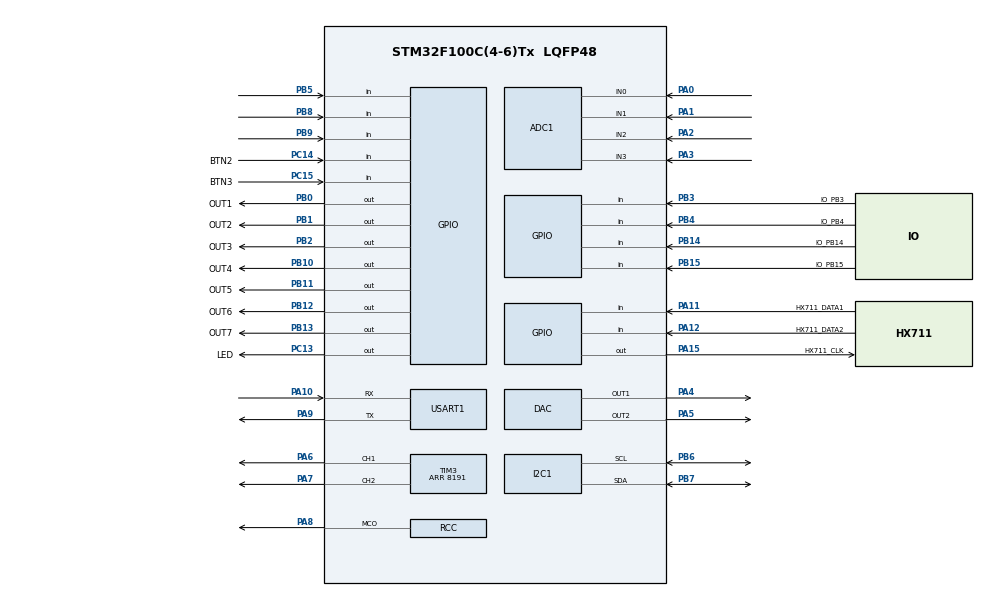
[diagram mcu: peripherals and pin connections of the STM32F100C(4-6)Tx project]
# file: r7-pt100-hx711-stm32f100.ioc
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ADC1.Channel-0\#ChannelRegularConversion=ADC_CHANNEL_0
ADC1.NbrOfConversionFlag=1
ADC1.Rank-0\#ChannelRegularConversion=1
ADC1.SamplingTime-0\#ChannelRegularConversion=ADC_SAMPLETIME_1CYCLE_5
ADC1.master=1
IWDG.Prescaler=IWDG_PRESCALER_32
IWDG.Reload=2000
Mcu.Family=STM32F1
Mcu.Name=STM32F100C(4-6)Tx
Mcu.Package=LQFP48
NVIC.PriorityGroup=NVIC_PRIORITYGROUP_4
PA0-WKUP.Signal=ADCx_IN0
PA1.Signal=ADCx_IN1
PA10.Mode=Asynchronous
PA10.Signal=USART1_RX
PA11.GPIO_Label=HX711_DATA1
PA11.Signal=GPIO_Input
PA12.GPIO_Label=HX711_DATA2
PA12.Signal=GPIO_Input
PA13.Mode=Serial_Wire
PA13.Signal=SYS_JTMS-SWDIO
PA14.Mode=Serial_Wire
PA14.Signal=SYS_JTCK-SWCLK
PA15.GPIO_Label=HX711_CLK
PA15.Signal=GPIO_Output
PA2.Signal=ADCx_IN2
PA3.Signal=ADCx_IN3
PA4.Signal=COMP_DAC1_group
PA5.Signal=COMP_DAC2_group
PA6.Signal=S_TIM3_CH1
PA7.Signal=S_TIM3_CH2
PA8.Mode=Clock-out
PA8.Signal=RCC_MCO
PA9.Mode=Asynchronous
PA9.Signal=USART1_TX
PB0.GPIO_Label=OUT1
PB0.Signal=GPIO_Output
PB1.GPIO_Label=OUT2
PB1.Signal=GPIO_Output
PB10.GPIO_Label=OUT4
PB10.Signal=GPIO_Output
PB11.GPIO_Label=OUT5
PB11.Signal=GPIO_Output
PB12.GPIO_Label=OUT6
PB12.Signal=GPIO_Output
PB13.GPIO_Label=OUT7
PB13.Signal=GPIO_Output
PB14.GPIO_Label=IO_PB14
PB14.Signal=GPIO_Input
PB15.GPIO_Label=IO_PB15
PB15.Signal=GPIO_Input
PB2.GPIO_Label=OUT3
PB2.Signal=GPIO_Output
PB3.GPIO_Label=IO_PB3
PB3.Signal=GPIO_Input
PB4.GPIO_Label=IO_PB4
PB4.Signal=GPIO_Input
PB5.GPIO_PuPd=GPIO_PULLUP
PB5.Signal=GPIO_Input
PB6.Mode=I2C
PB6.Signal=I2C1_SCL
PB7.Mode=I2C
PB7.Signal=I2C1_SDA
PB8.GPIO_PuPd=GPIO_PULLUP
PB8.Signal=GPIO_Input
PB9.GPIO_PuPd=GPIO_PULLUP
PB9.Signal=GPIO_Input
PC13-TAMPER-RTC.GPIO_Label=LED
PC13-TAMPER-RTC.Signal=GPIO_Output
PC14-OSC32_IN.GPIO_Label=BTN2
PC14-OSC32_IN.Signal=GPIO_Input
PC15-OSC32_OUT.GPIO_Label=BTN3
PC15-OSC32_OUT.Signal=GPIO_Input
PD0-OSC_IN.Mode=HSE-External-Oscillator
PD0-OSC_IN.Signal=RCC_OSC_IN
PD1-OSC_OUT.Mode=HSE-External-Oscillator
PD1-OSC_OUT.Signal=RCC_OSC_OUT
ProjectManager.HeapSize=0x200
ProjectManager.StackSize=0x400
ProjectManager.TargetToolchain=STM32CubeIDE
RCC.AHBFreq_Value=24000000
RCC.APB1Freq_Value=24000000
RCC.APB1TimFreq_Value=24000000
RCC.APB2Freq_Value=24000000
RCC.APB2TimFreq_Value=24000000
RCC.HCLKFreq_Value=24000000
RCC.PLLMUL=RCC_PLL_MUL3
RCC.PLLSource=RCC_PLLSOURCE_HSE
RCC.RCC_MCOSource=RCC_MCO1SOURCE_PLLCLK
RCC.SYSCLKFreq_VALUE=24000000
RCC.SYSCLKSource=RCC_SYSCLKSOURCE_PLLCLK
SH.ADCx_IN0.0=ADC1_IN0,IN0
SH.ADCx_IN1.0=ADC1_IN1,IN1
SH.ADCx_IN2.0=ADC1_IN2,IN2
SH.ADCx_IN3.0=ADC1_IN3,IN3
SH.COMP_DAC1_group.0=DAC_OUT1,DAC_OUT1
SH.COMP_DAC2_group.0=DAC_OUT2,DAC_OUT2
SH.S_TIM3_CH1.0=TIM3_CH1,PWM Generation1 CH1
SH.S_TIM3_CH2.0=TIM3_CH2,PWM Generation2 CH2
TIM3.Channel-PWM\ Generation1\ CH1=TIM_CHANNEL_1
TIM3.Channel-PWM\ Generation2\ CH2=TIM_CHANNEL_2
TIM3.Period=8191
USART1.VirtualMode=VM_ASYNC
VP_IWDG_VS_IWDG.Mode=IWDG_Activate
VP_TIM3_VS_ClockSourceINT.Mode=Internal
board=custom

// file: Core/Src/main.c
/* USER CODE BEGIN Header */
/**
  ******************************************************************************
  * @file           : main.c
  * @brief          : Main program body
  ******************************************************************************
  * @attention
  *
  * <h2><center>&copy; Copyright (c) 2020 STMicroelectronics.
  * All rights reserved.</center></h2>
  *
  * This software component is licensed by ST under BSD 3-Clause license,
  * the "License"; You may not use this file except in compliance with the
  * License. You may obtain a copy of the License at:
  *                        opensource.org/licenses/BSD-3-Clause
  *
  ******************************************************************************
  */
/* USER CODE END Header */
#include "main.h"

/* USER CODE BEGIN Includes */

#include <stdio.h>
#include "adc_hx711.h"

/* USER CODE END Includes */

void SystemClock_Config(void);
static void MX_GPIO_Init(void);
static void MX_ADC1_Init(void);
static void MX_DAC_Init(void);
static void MX_I2C1_Init(void);
static void MX_TIM3_Init(void);
static void MX_USART1_UART_Init(void);
static void MX_IWDG_Init(void);

/* USER CODE BEGIN 0 */

int __io_putchar(int ch)
{
	while (!LL_USART_IsActiveFlag_TXE(USART1))
	{};
	LL_USART_TransmitData8(USART1, ch);
	return 0;
}

/* USER CODE END 0 */

int main(void)
{

  /* MCU Configuration--------------------------------------------------------*/

  /* Reset of all peripherals, Initializes the Flash interface and the Systick. */

  LL_APB2_GRP1_EnableClock(LL_APB2_GRP1_PERIPH_AFIO);
  LL_APB1_GRP1_EnableClock(LL_APB1_GRP1_PERIPH_PWR);

  NVIC_SetPriorityGrouping(NVIC_PRIORITYGROUP_4);

  /* System interrupt init*/

  /** NOJTAG: JTAG-DP Disabled and SW-DP Enabled
  */
  LL_GPIO_AF_Remap_SWJ_NOJTAG();

  /* Configure the system clock */
  SystemClock_Config();

  /* Initialize all configured peripherals */
  MX_GPIO_Init();
  MX_ADC1_Init();
  MX_DAC_Init();
  MX_I2C1_Init();
  MX_TIM3_Init();
  MX_USART1_UART_Init();
  MX_IWDG_Init();
  /* USER CODE BEGIN 2 */

  // инициализация ADC
  ADC_HX711_Init();
  /* USER CODE END 2 */

  /* Infinite loop */
  /* USER CODE BEGIN WHILE */
  printf("\r\n---------------------------------\r\n");
  printf("Digital converter PT100\r\n");

  while (1)
  {
	  LL_GPIO_TogglePin(LED_GPIO_Port, LED_Pin);
	  ADC_HX711_Process();

	  LL_IWDG_ReloadCounter(IWDG);

    /* USER CODE END WHILE */

  }
}

void SystemClock_Config(void)
{
  LL_RCC_HSE_Enable();

   /* Wait till HSE is ready */
  while(LL_RCC_HSE_IsReady() != 1)
  {

  }
  LL_RCC_LSI_Enable();

   /* Wait till LSI is ready */
  while(LL_RCC_LSI_IsReady() != 1)
  {

  }
  LL_RCC_PLL_ConfigDomain_SYS(LL_RCC_PLLSOURCE_HSE_DIV_1, LL_RCC_PLL_MUL_3);
  LL_RCC_PLL_Enable();

   /* Wait till PLL is ready */
  while(LL_RCC_PLL_IsReady() != 1)
  {

  }
  LL_RCC_SetAHBPrescaler(LL_RCC_SYSCLK_DIV_1);
  LL_RCC_SetAPB1Prescaler(LL_RCC_APB1_DIV_1);
  LL_RCC_SetAPB2Prescaler(LL_RCC_APB2_DIV_1);
  LL_RCC_SetSysClkSource(LL_RCC_SYS_CLKSOURCE_PLL);

   /* Wait till System clock is ready */
  while(LL_RCC_GetSysClkSource() != LL_RCC_SYS_CLKSOURCE_STATUS_PLL)
  {

  }
  LL_Init1msTick(24000000);
  LL_SetSystemCoreClock(24000000);
  LL_RCC_ConfigMCO(LL_RCC_MCO1SOURCE_PLLCLK_DIV_2);
  LL_RCC_SetADCClockSource(LL_RCC_ADC_CLKSRC_PCLK2_DIV_2);
}

static void MX_ADC1_Init(void)
{

  LL_ADC_InitTypeDef ADC_InitStruct = {0};
  LL_ADC_REG_InitTypeDef ADC_REG_InitStruct = {0};

  LL_GPIO_InitTypeDef GPIO_InitStruct = {0};

  /* Peripheral clock enable */
  LL_APB2_GRP1_EnableClock(LL_APB2_GRP1_PERIPH_ADC1);

  LL_APB2_GRP1_EnableClock(LL_APB2_GRP1_PERIPH_GPIOA);
  /**ADC1 GPIO Configuration
  PA0-WKUP   ------> ADC1_IN0
  PA1   ------> ADC1_IN1
  PA2   ------> ADC1_IN2
  PA3   ------> ADC1_IN3
  */
  GPIO_InitStruct.Pin = LL_GPIO_PIN_0|LL_GPIO_PIN_1|LL_GPIO_PIN_2|LL_GPIO_PIN_3;
  GPIO_InitStruct.Mode = LL_GPIO_MODE_ANALOG;
  LL_GPIO_Init(GPIOA, &GPIO_InitStruct);

  /** Common config
  */
  ADC_InitStruct.DataAlignment = LL_ADC_DATA_ALIGN_RIGHT;
  ADC_InitStruct.SequencersScanMode = LL_ADC_SEQ_SCAN_DISABLE;
  LL_ADC_Init(ADC1, &ADC_InitStruct);
  ADC_REG_InitStruct.TriggerSource = LL_ADC_REG_TRIG_SOFTWARE;
  ADC_REG_InitStruct.SequencerLength = LL_ADC_REG_SEQ_SCAN_DISABLE;
  ADC_REG_InitStruct.SequencerDiscont = LL_ADC_REG_SEQ_DISCONT_DISABLE;
  ADC_REG_InitStruct.ContinuousMode = LL_ADC_REG_CONV_SINGLE;
  ADC_REG_InitStruct.DMATransfer = LL_ADC_REG_DMA_TRANSFER_NONE;
  LL_ADC_REG_Init(ADC1, &ADC_REG_InitStruct);
  /** Configure Regular Channel
  */
  LL_ADC_REG_SetSequencerRanks(ADC1, LL_ADC_REG_RANK_1, LL_ADC_CHANNEL_0);
  LL_ADC_SetChannelSamplingTime(ADC1, LL_ADC_CHANNEL_0, LL_ADC_SAMPLINGTIME_1CYCLE_5);

}

static void MX_DAC_Init(void)
{

  LL_DAC_InitTypeDef DAC_InitStruct = {0};

  LL_GPIO_InitTypeDef GPIO_InitStruct = {0};

  /* Peripheral clock enable */
  LL_APB1_GRP1_EnableClock(LL_APB1_GRP1_PERIPH_DAC1);

  LL_APB2_GRP1_EnableClock(LL_APB2_GRP1_PERIPH_GPIOA);
  /**DAC GPIO Configuration
  PA4   ------> DAC_OUT1
  PA5   ------> DAC_OUT2
  */
  GPIO_InitStruct.Pin = LL_GPIO_PIN_4|LL_GPIO_PIN_5;
  GPIO_InitStruct.Mode = LL_GPIO_MODE_ANALOG;
  LL_GPIO_Init(GPIOA, &GPIO_InitStruct);

  /** DAC channel OUT1 config
  */
  DAC_InitStruct.TriggerSource = LL_DAC_TRIG_SOFTWARE;
  DAC_InitStruct.WaveAutoGeneration = LL_DAC_WAVE_AUTO_GENERATION_NONE;
  DAC_InitStruct.OutputBuffer = LL_DAC_OUTPUT_BUFFER_ENABLE;
  LL_DAC_Init(DAC, LL_DAC_CHANNEL_1, &DAC_InitStruct);
  LL_DAC_DisableTrigger(DAC, LL_DAC_CHANNEL_1);
  /** DAC channel OUT2 config
  */
  LL_DAC_Init(DAC, LL_DAC_CHANNEL_2, &DAC_InitStruct);
  LL_DAC_DisableTrigger(DAC, LL_DAC_CHANNEL_2);

}

static void MX_I2C1_Init(void)
{

  LL_I2C_InitTypeDef I2C_InitStruct = {0};

  LL_GPIO_InitTypeDef GPIO_InitStruct = {0};

  LL_APB2_GRP1_EnableClock(LL_APB2_GRP1_PERIPH_GPIOB);
  /**I2C1 GPIO Configuration
  PB6   ------> I2C1_SCL
  PB7   ------> I2C1_SDA
  */
  GPIO_InitStruct.Pin = LL_GPIO_PIN_6|LL_GPIO_PIN_7;
  GPIO_InitStruct.Mode = LL_GPIO_MODE_ALTERNATE;
  GPIO_InitStruct.Speed = LL_GPIO_SPEED_FREQ_HIGH;
  GPIO_InitStruct.OutputType = LL_GPIO_OUTPUT_OPENDRAIN;
  LL_GPIO_Init(GPIOB, &GPIO_InitStruct);

  /* Peripheral clock enable */
  LL_APB1_GRP1_EnableClock(LL_APB1_GRP1_PERIPH_I2C1);

  /** I2C Initialization
  */
  LL_I2C_DisableOwnAddress2(I2C1);
  LL_I2C_DisableGeneralCall(I2C1);
  LL_I2C_EnableClockStretching(I2C1);
  I2C_InitStruct.PeripheralMode = LL_I2C_MODE_I2C;
  I2C_InitStruct.ClockSpeed = 100000;
  I2C_InitStruct.DutyCycle = LL_I2C_DUTYCYCLE_2;
  I2C_InitStruct.OwnAddress1 = 0;
  I2C_InitStruct.TypeAcknowledge = LL_I2C_ACK;
  I2C_InitStruct.OwnAddrSize = LL_I2C_OWNADDRESS1_7BIT;
  LL_I2C_Init(I2C1, &I2C_InitStruct);
  LL_I2C_SetOwnAddress2(I2C1, 0);

}

static void MX_IWDG_Init(void)
{

  LL_IWDG_Enable(IWDG);
  LL_IWDG_EnableWriteAccess(IWDG);
  LL_IWDG_SetPrescaler(IWDG, LL_IWDG_PRESCALER_32);
  LL_IWDG_SetReloadCounter(IWDG, 2000);
  while (LL_IWDG_IsReady(IWDG) != 1)
  {
  }

  LL_IWDG_ReloadCounter(IWDG);

}

static void MX_TIM3_Init(void)
{

  LL_TIM_InitTypeDef TIM_InitStruct = {0};
  LL_TIM_OC_InitTypeDef TIM_OC_InitStruct = {0};

  LL_GPIO_InitTypeDef GPIO_InitStruct = {0};

  /* Peripheral clock enable */
  LL_APB1_GRP1_EnableClock(LL_APB1_GRP1_PERIPH_TIM3);

  TIM_InitStruct.Prescaler = 0;
  TIM_InitStruct.CounterMode = LL_TIM_COUNTERMODE_UP;
  TIM_InitStruct.Autoreload = 8191;
  TIM_InitStruct.ClockDivision = LL_TIM_CLOCKDIVISION_DIV1;
  LL_TIM_Init(TIM3, &TIM_InitStruct);
  LL_TIM_DisableARRPreload(TIM3);
  LL_TIM_SetClockSource(TIM3, LL_TIM_CLOCKSOURCE_INTERNAL);
  LL_TIM_OC_EnablePreload(TIM3, LL_TIM_CHANNEL_CH1);
  TIM_OC_InitStruct.OCMode = LL_TIM_OCMODE_PWM1;
  TIM_OC_InitStruct.OCState = LL_TIM_OCSTATE_DISABLE;
  TIM_OC_InitStruct.OCNState = LL_TIM_OCSTATE_DISABLE;
  TIM_OC_InitStruct.CompareValue = 0;
  TIM_OC_InitStruct.OCPolarity = LL_TIM_OCPOLARITY_HIGH;
  LL_TIM_OC_Init(TIM3, LL_TIM_CHANNEL_CH1, &TIM_OC_InitStruct);
  LL_TIM_OC_DisableFast(TIM3, LL_TIM_CHANNEL_CH1);
  LL_TIM_OC_EnablePreload(TIM3, LL_TIM_CHANNEL_CH2);
  TIM_OC_InitStruct.OCState = LL_TIM_OCSTATE_DISABLE;
  TIM_OC_InitStruct.OCNState = LL_TIM_OCSTATE_DISABLE;
  LL_TIM_OC_Init(TIM3, LL_TIM_CHANNEL_CH2, &TIM_OC_InitStruct);
  LL_TIM_OC_DisableFast(TIM3, LL_TIM_CHANNEL_CH2);
  LL_TIM_SetTriggerOutput(TIM3, LL_TIM_TRGO_RESET);
  LL_TIM_DisableMasterSlaveMode(TIM3);
  LL_APB2_GRP1_EnableClock(LL_APB2_GRP1_PERIPH_GPIOA);
  /**TIM3 GPIO Configuration
  PA6   ------> TIM3_CH1
  PA7   ------> TIM3_CH2
  */
  GPIO_InitStruct.Pin = LL_GPIO_PIN_6|LL_GPIO_PIN_7;
  GPIO_InitStruct.Mode = LL_GPIO_MODE_ALTERNATE;
  GPIO_InitStruct.Speed = LL_GPIO_SPEED_FREQ_LOW;
  GPIO_InitStruct.OutputType = LL_GPIO_OUTPUT_PUSHPULL;
  LL_GPIO_Init(GPIOA, &GPIO_InitStruct);

}

static void MX_USART1_UART_Init(void)
{

  LL_USART_InitTypeDef USART_InitStruct = {0};

  LL_GPIO_InitTypeDef GPIO_InitStruct = {0};

  /* Peripheral clock enable */
  LL_APB2_GRP1_EnableClock(LL_APB2_GRP1_PERIPH_USART1);

  LL_APB2_GRP1_EnableClock(LL_APB2_GRP1_PERIPH_GPIOA);
  /**USART1 GPIO Configuration
  PA9   ------> USART1_TX
  PA10   ------> USART1_RX
  */
  GPIO_InitStruct.Pin = LL_GPIO_PIN_9;
  GPIO_InitStruct.Mode = LL_GPIO_MODE_ALTERNATE;
  GPIO_InitStruct.Speed = LL_GPIO_SPEED_FREQ_HIGH;
  GPIO_InitStruct.OutputType = LL_GPIO_OUTPUT_PUSHPULL;
  LL_GPIO_Init(GPIOA, &GPIO_InitStruct);

  GPIO_InitStruct.Pin = LL_GPIO_PIN_10;
  GPIO_InitStruct.Mode = LL_GPIO_MODE_FLOATING;
  LL_GPIO_Init(GPIOA, &GPIO_InitStruct);

  USART_InitStruct.BaudRate = 115200;
  USART_InitStruct.DataWidth = LL_USART_DATAWIDTH_8B;
  USART_InitStruct.StopBits = LL_USART_STOPBITS_1;
  USART_InitStruct.Parity = LL_USART_PARITY_NONE;
  USART_InitStruct.TransferDirection = LL_USART_DIRECTION_TX_RX;
  USART_InitStruct.HardwareFlowControl = LL_USART_HWCONTROL_NONE;
  USART_InitStruct.OverSampling = LL_USART_OVERSAMPLING_16;
  LL_USART_Init(USART1, &USART_InitStruct);
  LL_USART_ConfigAsyncMode(USART1);
  LL_USART_Enable(USART1);

}

static void MX_GPIO_Init(void)
{
  LL_GPIO_InitTypeDef GPIO_InitStruct = {0};

  /* GPIO Ports Clock Enable */
  LL_APB2_GRP1_EnableClock(LL_APB2_GRP1_PERIPH_GPIOC);
  LL_APB2_GRP1_EnableClock(LL_APB2_GRP1_PERIPH_GPIOD);
  LL_APB2_GRP1_EnableClock(LL_APB2_GRP1_PERIPH_GPIOA);
  LL_APB2_GRP1_EnableClock(LL_APB2_GRP1_PERIPH_GPIOB);

  /**/
  LL_GPIO_ResetOutputPin(LED_GPIO_Port, LED_Pin);

  /**/
  LL_GPIO_ResetOutputPin(GPIOB, OUT1_Pin|OUT2_Pin|OUT3_Pin|OUT4_Pin
                          |OUT5_Pin|OUT6_Pin|OUT7_Pin);

  /**/
  LL_GPIO_ResetOutputPin(HX711_CLK_GPIO_Port, HX711_CLK_Pin);

  /**/
  GPIO_InitStruct.Pin = LED_Pin;
  GPIO_InitStruct.Mode = LL_GPIO_MODE_OUTPUT;
  GPIO_InitStruct.Speed = LL_GPIO_SPEED_FREQ_LOW;
  GPIO_InitStruct.OutputType = LL_GPIO_OUTPUT_PUSHPULL;
  LL_GPIO_Init(LED_GPIO_Port, &GPIO_InitStruct);

  /**/
  GPIO_InitStruct.Pin = BTN2_Pin|BTN3_Pin;
  GPIO_InitStruct.Mode = LL_GPIO_MODE_FLOATING;
  LL_GPIO_Init(GPIOC, &GPIO_InitStruct);

  /**/
  GPIO_InitStruct.Pin = OUT1_Pin|OUT2_Pin|OUT3_Pin|OUT4_Pin
                          |OUT5_Pin|OUT6_Pin|OUT7_Pin;
  GPIO_InitStruct.Mode = LL_GPIO_MODE_OUTPUT;
  GPIO_InitStruct.Speed = LL_GPIO_SPEED_FREQ_LOW;
  GPIO_InitStruct.OutputType = LL_GPIO_OUTPUT_PUSHPULL;
  LL_GPIO_Init(GPIOB, &GPIO_InitStruct);

  /**/
  GPIO_InitStruct.Pin = IO_PB14_Pin|IO_PB15_Pin|IO_PB3_Pin|IO_PB4_Pin;
  GPIO_InitStruct.Mode = LL_GPIO_MODE_FLOATING;
  LL_GPIO_Init(GPIOB, &GPIO_InitStruct);

  /**/
  GPIO_InitStruct.Pin = LL_GPIO_PIN_8;
  GPIO_InitStruct.Mode = LL_GPIO_MODE_ALTERNATE;
  GPIO_InitStruct.Speed = LL_GPIO_SPEED_FREQ_LOW;
  GPIO_InitStruct.OutputType = LL_GPIO_OUTPUT_PUSHPULL;
  LL_GPIO_Init(GPIOA, &GPIO_InitStruct);

  /**/
  GPIO_InitStruct.Pin = HX711_DATA1_Pin|HX711_DATA2_Pin;
  GPIO_InitStruct.Mode = LL_GPIO_MODE_FLOATING;
  LL_GPIO_Init(GPIOA, &GPIO_InitStruct);

  /**/
  GPIO_InitStruct.Pin = HX711_CLK_Pin;
  GPIO_InitStruct.Mode = LL_GPIO_MODE_OUTPUT;
  GPIO_InitStruct.Speed = LL_GPIO_SPEED_FREQ_LOW;
  GPIO_InitStruct.OutputType = LL_GPIO_OUTPUT_PUSHPULL;
  LL_GPIO_Init(HX711_CLK_GPIO_Port, &GPIO_InitStruct);

  /**/
  GPIO_InitStruct.Pin = LL_GPIO_PIN_5|LL_GPIO_PIN_8|LL_GPIO_PIN_9;
  GPIO_InitStruct.Mode = LL_GPIO_MODE_INPUT;
  GPIO_InitStruct.Pull = LL_GPIO_PULL_UP;
  LL_GPIO_Init(GPIOB, &GPIO_InitStruct);

}

void Error_Handler(void)
{
}

/************************ (C) COPYRIGHT STMicroelectronics *****END OF FILE****/
